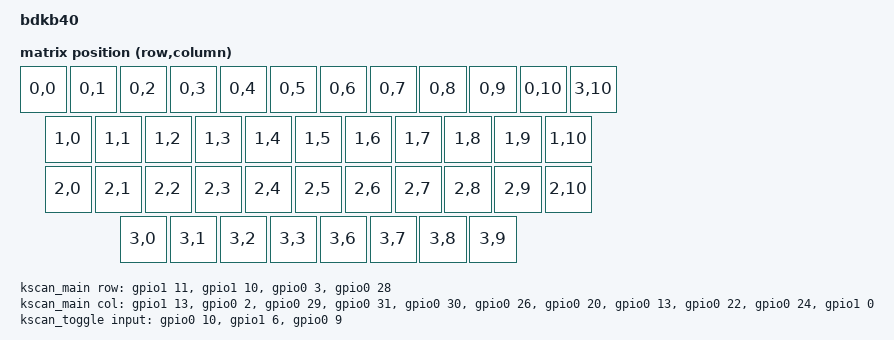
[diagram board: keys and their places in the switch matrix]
// This file was generated from a template. Edit it to match your keyboard.
// See https://docs.zephyrproject.org/4.1.0/hardware/porting/board_porting.html
// and https://zmk.dev/docs/development/hardware-integration/new-shield for more
// instructions.

/dts-v1/;
#include <nordic/nrf52840_qiaa.dtsi>
// #include <common/nordic/nrf52840_uf2_boot_mode.dtsi>
#include <dt-bindings/zmk/matrix_transform.h>
#include <dt-bindings/zmk/outputs.h>

#include "bdkb40-pinctrl.dtsi"
#include "bdkb40-layouts.dtsi"

/ {
    model = "bdkb40";
    compatible = "bdkb40";

    chosen {
        zephyr,code-partition = &code_partition;
        zephyr,sram = &sram0;
        zephyr,flash = &flash0;
        // Uncomment this if you enabled one of the "vddh" nodes below.
        zmk,battery = &builtin_fuel_gauge;
        zmk,physical-layout = &default_layout;
		// zmk,kscan = &kscan_main;
    };
    
    kscan_main: kscan_main {
        // If the hardware does not use a switch matrix, change this to the
        // appropriate driver and update the properties below to match.
        // See https://zmk.dev/docs/config/kscan for supported key scan drivers.
        compatible = "zmk,kscan-gpio-matrix";
        // Set this to "col2row" or "row2col" to match the hardware. If using
        // "row2col", change the col-gpios to (GPIO_ACTIVE_HIGH | GPIO_PULL_DOWN)
        // and the row-gpios to GPIO_ACTIVE_HIGH.
        diode-direction = "col2row";
        wakeup-source;

        // Replace these comments with the GPIO pins in the matrix.
        // See https://zmk.dev/docs/development/hardware-integration/new-shield#shield-overlays
        col-gpios
            = <&gpio1 13 GPIO_ACTIVE_HIGH>  // c0
            , <&gpio0  2 GPIO_ACTIVE_HIGH>  // c1
            , <&gpio0 29 GPIO_ACTIVE_HIGH>  // c2
            , <&gpio0 31 GPIO_ACTIVE_HIGH>  // c3
            , <&gpio0 30 GPIO_ACTIVE_HIGH>  // c4
            , <&gpio0 26 GPIO_ACTIVE_HIGH>  // c5
            , <&gpio0 20 GPIO_ACTIVE_HIGH>  // c6
            , <&gpio0 13 GPIO_ACTIVE_HIGH>  // c7
            , <&gpio0 22 GPIO_ACTIVE_HIGH>  // c8
            , <&gpio0 24 GPIO_ACTIVE_HIGH>  // c9
            , <&gpio1  0 GPIO_ACTIVE_HIGH>  // c10
            ;

        row-gpios
            = <&gpio1 11 (GPIO_ACTIVE_HIGH | GPIO_PULL_DOWN)>  // r0
            , <&gpio1 10 (GPIO_ACTIVE_HIGH | GPIO_PULL_DOWN)>  // r1
            , <&gpio0  3 (GPIO_ACTIVE_HIGH | GPIO_PULL_DOWN)>  // r2
            , <&gpio0 28 (GPIO_ACTIVE_HIGH | GPIO_PULL_DOWN)>  // r3
            ;
    };

	kscan_toggle: kscan_toggle {
		compatible = "zmk,kscan-gpio-direct";
		label = "Toggle KSCAN";
        toggle-mode;
		wakeup-source;
		input-gpios
			= <&gpio0 10 GPIO_ACTIVE_LOW>
			, <&gpio1  6 GPIO_ACTIVE_LOW>
			, <&gpio0  9 GPIO_ACTIVE_LOW>
			;
	};

    default_transform: default_transform {
        // See https://zmk.dev/docs/development/hardware-integration/new-shield#matrix-transform
        // for how to configure this
        compatible = "zmk,matrix-transform";
        columns = <11>;
        rows = <4>;
        map = <
            RC(0, 0) RC(0, 1) RC(0, 2) RC(0, 3) RC(0, 4) RC(0, 5) RC(0, 6) RC(0, 7) RC(0, 8) RC(0, 9) RC(0, 10) RC(3, 10)
            RC(1, 0)    RC(1, 1) RC(1, 2) RC(1, 3) RC(1, 4) RC(1, 5) RC(1, 6) RC(1, 7) RC(1, 8) RC(1, 9)        RC(1, 10)
            RC(2, 0)       RC(2, 1) RC(2, 2) RC(2, 3) RC(2, 4) RC(2, 5) RC(2, 6) RC(2, 7) RC(2, 8) RC(2, 9)     RC(2, 10)
            RC(3, 0)    RC(3, 1)   RC(3, 2)         RC(3, 3)          RC(3, 6)         RC(3, 7)     RC(3, 8)    RC(3, 9) 
        >;
    };

    leds {
        compatible = "gpio-leds";

        // If you have a GPIO routed to a status LED, set it here.
        // Otherwise, delete this block.
        red_led: led_0 {
            gpios = <&gpio0  4 GPIO_ACTIVE_LOW>;
        };
        blue_led: led_1 {
            gpios = <&gpio0  7 GPIO_ACTIVE_LOW>;
        };
        green_led: led_2 {
            gpios = <&gpio0 12 GPIO_ACTIVE_LOW>;
        };
    };

    // If you are powering the SoC from the VDDH pin, uncomment this block.
    // Otherwise, delete it.

    // vbatt: vbatt {
    //     compatible = "zmk,battery-nrf-vddh";
    // };

    // If you are powering the SoC from the VDD pin and you have a voltage divider
    // routed to an analog pin to read the battery voltage, uncomment this block
    // and assign the correct ADC channel and resistance values.
    // Otherwise, delete it.

    // vbatt: vbatt {
    //     compatible = "voltage-divider";
    //     io-channels = <&adc 2>;
    //     output-ohms = <2000000>;
    //     full-ohms = <(2000000 + 806000)>;
    // };
};

// Uncomment this to switch from the LDO to the DC/DC regulator on REG0.
// Do not enable the DC/DC regulator without an LC filter connected to the DCCH
// pin, or the keyboard will not boot until an LC filter is connected.
// &reg0 {
//     status = "okay";
// };

// Uncomment this to switch from the LDO to the DC/DC regulator on REG1.
// Do not enable the DC/DC regulator without an LC filter connected to the DCC
// pin, or the keyboard will not boot until an LC filter is connected.
// &reg1 {
//     regulator-initial-mode = <NRF5X_REG_MODE_DCDC>;
// };

&adc {
    status = "okay";
};

&gpiote {
    status = "okay";
};

&gpio0 {
    status = "okay";
};

&gpio1 {
    status = "okay";
};

&i2c0 {
    status = "okay";
    compatible = "nordic,nrf-twi";
    pinctrl-0 = <&i2c0_default>;
    pinctrl-1 = <&i2c0_sleep>;
    pinctrl-names = "default", "sleep";

    builtin_fuel_gauge: max17048@36 {
        compatible = "zmk,maxim-max17048";
        status = "okay";
        reg = <0x36>;
    };
};

&uart0 {
    compatible = "nordic,nrf-uarte";
    current-speed = <115200>;
    pinctrl-0 = <&uart0_default>;
    pinctrl-1 = <&uart0_sleep>;
    pinctrl-names = "default", "sleep";
};

// If you use the NFC pins as GPIOs, uncomment this. Otherwise, remove it.
// &uicr {
//     nfct-pins-as-gpios;
// };

zephyr_udc0: &usbd {
    status = "okay";
};

&flash0 {
    // Adjust this flash map as is necessary for your board. For more information, see
    // https://docs.zephyrproject.org/4.1.0/services/storage/flash_map/flash_map.html#relationship-with-devicetree
    partitions {
        compatible = "fixed-partitions";
        #address-cells = <1>;
        #size-cells = <1>;

        code_partition: partition@1000 {
            reg = <DT_SIZE_K(4) DT_SIZE_K(844)>;
        };

        // If using a bootloader with SoftDevice included, replace the code_partition
        // node above with the following. If using SoftDevice v7, change 26000 to 27000.

        // sd_partition: partition@0 {
        //     reg = <0x0 <DT_SIZE_K(4)>;
        // };
        // code_partition: partition@26000 {
        //     reg = <DT_SIZE_K(152) DT_SIZE_K(792)>;
        // };

        // The flash starting at 0x000d4000 and ending at
        // 0x000f3fff is reserved for use by the application.

        // Storage partition will be used by NVS if enabled.
        storage_partition: partition@d4000 {
            reg = <DT_SIZE_K(848) DT_SIZE_K(128)>;
        };

        boot_partition: partition@f4000 {
            reg = <DT_SIZE_K(976) DT_SIZE_K(48)>;
        };
    };
};
